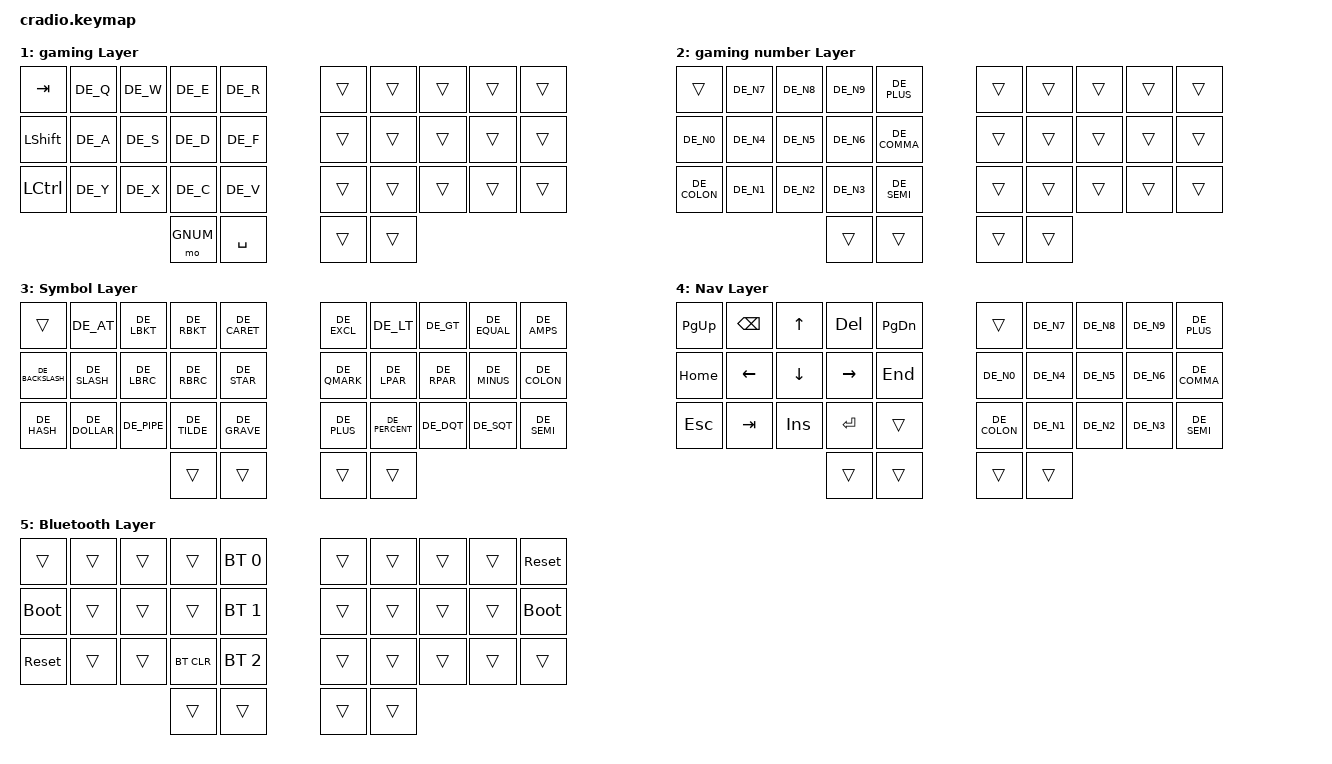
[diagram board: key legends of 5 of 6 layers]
#include <behaviors.dtsi>
#include <dt-bindings/zmk/keys.h>
#include <dt-bindings/zmk/bt.h>
#include <locale/keys_de.h>

#define DEFAULT 0
#define GAMING  1
#define GNUM    2
#define SYM     3
#define NAV     4
#define BT      5

#define L_HOME(k1, k2, k3, k4) &mt LSHIFT k1 &mt LALT k2 &mt LCTRL k3 &mt LGUI k4
#define R_HOME(k1, k2, k3, k4) &mt LGUI k1 &mt LCTRL k2 &mt LALT k3 &mt LSHIFT k4

#define COMBO(name, key_positions, binding) name { \
  timeout-ms = <50>; \
  key-positions = <key_positions>; \
  bindings = <binding>; \
};

/ {
    behaviors {
        lt: layer_tap {
            compatible = "zmk,behavior-hold-tap";
            #binding-cells = <2>;
            tapping-term-ms = <200>;
            flavor = "tap-preferred";
            bindings = <&mo>, <&kp>;
        };
    };

    conditional_layers {
        compatible = "zmk,conditional-layers";
          bt_layer {
            if-layers = <SYM NAV>;
            then-layer = <BT>;
        };
    };
    combos {
        compatible = "zmk,combos";
        COMBO(combo_toggle_gaming, 16 17 18 19, &tog GAMING)
        COMBO(combo_ae, 2 3, &kp DE_A_UMLAUT)
        COMBO(combo_ue, 12 13, &kp DE_U_UMLAUT)
        COMBO(combo_oe, 22 23, &kp DE_O_UMLAUT)
        COMBO(combo_esc, 1 2, &kp ESC)
        COMBO(combo_alt, 17 18, &sk LALT)
    };

    keymap {
        compatible = "zmk,keymap";

        default_layer {
            display-name = "Default Layer";
            bindings = <
                &kp J  &kp D  &kp U           &kp A        &kp X             &kp P           &kp H  &kp L         &kp M       &kp W
                L_HOME(C, T, I, E)                         &kp O             &kp B           R_HOME(N, R, S, G)
                &kp F  &kp V  &kp DE_SHARP_S  &kp Q        &kp LCTRL         &kp Y           &kp Z  &kp DE_COMMA  &kp DE_DOT  &kp K
                                              &lt SYM TAB  &kp ENTER         &kp SPACE       &lt NAV BSPC
            >;
        };

        gaming_layer {
            display-name = "gaming Layer";
            bindings = <
                &kp TAB    &kp DE_Q   &kp DE_W   &kp DE_E   &kp DE_R       &trans      &trans      &trans      &trans      &trans
                &kp LSHIFT &kp DE_A   &kp DE_S   &kp DE_D   &kp DE_F       &trans      &trans      &trans      &trans      &trans
                &kp LCTRL  &kp DE_Y   &kp DE_X   &kp DE_C   &kp DE_V       &trans      &trans      &trans      &trans      &trans
                                                 &mo GNUM   &kp SPACE      &trans      &trans
            >;
        };
        gnum_layer {
            display-name = "gaming number Layer";
            bindings = <
                 &trans        &kp DE_N7  &kp DE_N8  &kp DE_N9  &kp DE_PLUS     &trans      &trans      &trans      &trans      &trans
                 &kp DE_N0     &kp DE_N4  &kp DE_N5  &kp DE_N6  &kp DE_COMMA    &trans      &trans      &trans      &trans      &trans
                 &kp DE_COLON  &kp DE_N1  &kp DE_N2  &kp DE_N3  &kp DE_SEMI     &trans      &trans      &trans      &trans      &trans
                                                     &trans     &trans          &trans      &trans 
            >;
        };
        symbol_layer {
            display-name = "Symbol Layer";
            bindings = <
                 &trans            &kp DE_AT      &kp DE_LBKT  &kp DE_RBKT   &kp DE_CARET  &kp DE_EXCL   &kp DE_LT       &kp DE_GT    &kp DE_EQUAL  &kp DE_AMPS
                 &kp DE_BACKSLASH  &kp DE_SLASH   &kp DE_LBRC  &kp DE_RBRC   &kp DE_STAR   &kp DE_QMARK  &kp DE_LPAR     &kp DE_RPAR  &kp DE_MINUS  &kp DE_COLON
                 &kp DE_HASH       &kp DE_DOLLAR  &kp DE_PIPE  &kp DE_TILDE  &kp DE_GRAVE  &kp DE_PLUS   &kp DE_PERCENT  &kp DE_DQT   &kp DE_SQT    &kp DE_SEMI
                                                               &trans        &trans        &trans        &trans
            >;
        };

        nav_layer {
            display-name = "Nav Layer";
            bindings = <
                &kp PG_UP  &kp BSPC  &kp UP    &kp DEL    &kp PG_DN  &trans        &kp DE_N7  &kp DE_N8  &kp DE_N9  &kp DE_PLUS
                &kp HOME   &kp LEFT  &kp DOWN  &kp RIGHT  &kp END    &kp DE_N0     &kp DE_N4  &kp DE_N5  &kp DE_N6  &kp DE_COMMA
                &kp ESC    &kp TAB   &kp INS   &kp ENTER  &trans     &kp DE_COLON  &kp DE_N1  &kp DE_N2  &kp DE_N3  &kp DE_SEMI
                                               &trans     &trans     &trans     &trans
            >;
        };
        bt_layer {
            display-name = "Bluetooth Layer";
            bindings = <
                &trans       &trans  &trans  &trans      &bt BT_SEL 0  &trans  &trans  &trans  &trans  &sys_reset
                &bootloader  &trans  &trans  &trans      &bt BT_SEL 1  &trans  &trans  &trans  &trans  &bootloader
                &sys_reset   &trans  &trans  &bt BT_CLR  &bt BT_SEL 2  &trans  &trans  &trans  &trans  &trans
                                             &trans      &trans        &trans  &trans
            >;
        };
    };
};
